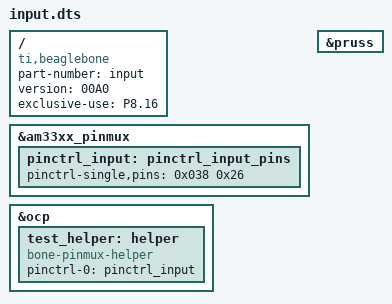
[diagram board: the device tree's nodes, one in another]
/*
 *
 */
/dts-v1/;
/plugin/;

/ {
    compatible = "ti,beaglebone", "ti,beaglebone-black";

    /* identification */
    part-number = "input";
    version     = "00A0";
    
    exclusive-use =  
        "P8.16";  

    fragment@0 {
        target = <&am33xx_pinmux>;
        __overlay__ {
        	pinctrl_input: pinctrl_input_pins {
        		pinctrl-single,pins = <
                        0x038 0x26  /* GPIO1_14 - Mode 6, Pull-Down, RxActive */ 
        		>;
        	};
        };
    };
    
    fragment@1 {
        target = <&ocp>;
        __overlay__ {
            test_helper: helper {  
                compatible = "bone-pinmux-helper"; 
                pinctrl-names = "default";
                pinctrl-0 = <&pinctrl_input>;
                status = "okay";
            };
        };
    };
    
    fragment@2{  
        target = <&pruss>;  
        __overlay__ {  
            status = "okay";  
        };  
    };  

};
